# SAM9X60 device description
Architecture: ARM926EJS; Family: SAM9; Series: SAM9X
Registers are 32-bit, read-write, no defined reset value unless marked. A register's access mark holds for its fields unless they carry their own. Offsets are from the block's base; [hi:lo] are bit positions; {n}, {i} and the like mark numbered series; 'fields as' and 'values as' point back to an identical list.

## OTPC — OTP Memory Controller
Instances: OTPC 0xEFF00000
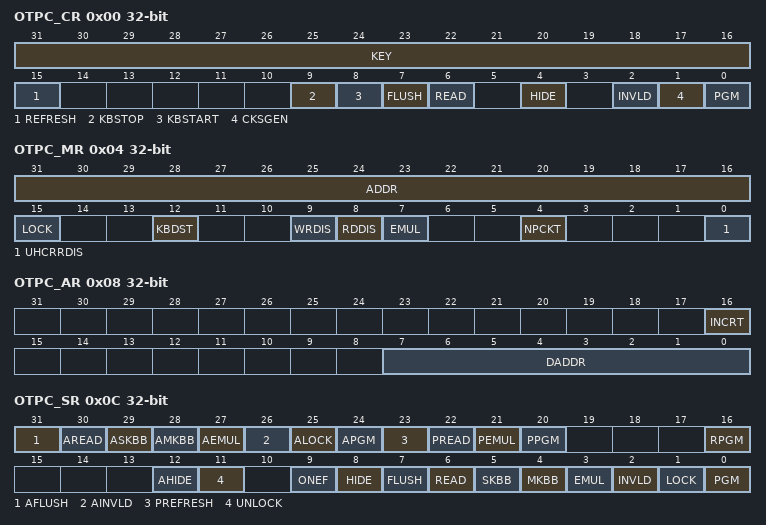
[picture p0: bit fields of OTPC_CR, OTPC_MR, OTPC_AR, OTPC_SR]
0x00 OTPC_CR wo — Control Register
  [31:16] KEY — Programming Key
  [15] REFRESH — Refresh the Area
  [9] KBSTOP — Key Bus Transfer Stop
  [8] KBSTART — Key Bus Transfer Start
  [7] FLUSH — Flush Temporary Registers
  [6] READ — Read Area
  [4] HIDE — Hide Packet
  [2] INVLD — Invalidate Packet
  [1] CKSGEN — Generate Checksum
  [0] PGM — Program Packet
0x04 OTPC_MR — Mode Register
  [31:16] ADDR — Address
  [15] LOCK
  [12] KBDST — Key Bus Destination
    0=TDES (The TDES is the destination of the key transfer.); 1=AES (The AES is the destination of the key transfer.)
  [9] WRDIS — Write Disable
  [8] RDDIS — Read Disable
  [7] EMUL — Emulation Enable
  [4] NPCKT — New Packet
  [0] UHCRRDIS — User Hardware Configuration Register Read Disable
0x08 OTPC_AR — Address Register
  [16] INCRT — Increment Type
    0=AFTER_READ (Increment DADDR after a read of OTPC_DR.); 1=AFTER_WRITE (Increment DADDR after a write of OTPC_DR.)
  [7:0] DADDR — Data Address
0x0C OTPC_SR ro — Status Register
  [31] AFLUSH — Engineering Flush On-Going
  [30] AREAD — Engineering Read On-Going
  [29] ASKBB — Engineering Slave Key Bus Busy
  [28] AMKBB — Engineering Master Key Bus Busy
  [27] AEMUL — Engineering Emulation Enabled
  [26] AINVLD — Engineering Invalidation On-Going
  [25] ALOCK — Engineering Lock On-Going
  [24] APGM — Engineering Programming On-Going
  [23] PREFRESH — Patch Refresh On-Going
  [22] PREAD — Patch Read On-Going
  [21] PEMUL — Patch Emulation Enabled
  [20] PPGM — Patch Programming On-Going
  [16] RPGM — ROM Programming On-Going
  [12] AHIDE — Hiding On-Going
  [11] UNLOCK — OTP Registers Unlocked
  [9] ONEF — One Found
  [8] HIDE — Hiding On-Going
  [7] FLUSH — Flush On-Going
  [6] READ — Read On-Going
  [5] SKBB — Slave Key Bus Busy
  [4] MKBB — Master Key Bus Busy
  [3] EMUL — Emulation Enabled
  [2] INVLD — Invalidation On-Going
  [1] LOCK — Lock On-Going
  [0] PGM — Programming On-Going
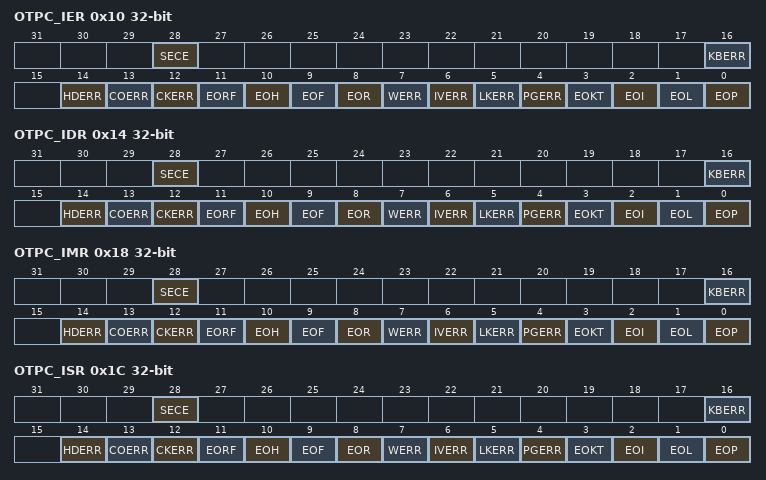
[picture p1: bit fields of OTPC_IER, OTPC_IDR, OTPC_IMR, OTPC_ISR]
0x10 OTPC_IER wo — Interrupt Enable Register
  [28] SECE — Security and/or Safety Event Interrupt Enable
  [16] KBERR — Key Bus Error Interrupt Enable
  [14] HDERR — Hide Error Interrupt Enable
  [13] COERR — Corruption Error Interrupt Enable
  [12] CKERR — Checksum Check Error Interrupt Enable
  [11] EORF — End Of Refresh Interrupt Enable
  [10] EOH — End Of Hide Interrupt Enable
  [9] EOF — End Of Flush Interrupt Enable
  [8] EOR — End Of Read Interrupt Enable
  [7] WERR — Write Error Interrupt Enable
  [6] IVERR — Invalidation Error Interrupt Enable
  [5] LKERR — Locking Error Interrupt Enable
  [4] PGERR — Programming Error Interrupt Enable
  [3] EOKT — End Of Key Transfer Interrupt Enable
  [2] EOI — End Of Invalidation Interrupt Enable
  [1] EOL — End Of Locking Interrupt Enable
  [0] EOP — End Of Programming Interrupt Enable
0x14 OTPC_IDR wo — Interrupt Disable Register
  [28] SECE — Security and/or Safety Event Interrupt Disable
  [16] KBERR — Key Bus Error Interrupt Disable
  [14] HDERR — Hide Error Interrupt Disable
  [13] COERR — Corruption Error Interrupt Disable
  [12] CKERR — Checksum Check Error Interrupt Disable
  [11] EORF — End Of Refresh Interrupt Disable
  [10] EOH — End Of Hide Interrupt Disable
  [9] EOF — End Of Flush Interrupt Disable
  [8] EOR — End Of Read Interrupt Disable
  [7] WERR — Write Error Interrupt Disable
  [6] IVERR — Invalidation Error Interrupt Disable
  [5] LKERR — Locking Error Interrupt Disable
  [4] PGERR — Programming Error Interrupt Disable
  [3] EOKT — End Of Key Transfer Interrupt Disable
  [2] EOI — End Of Invalidation Interrupt Disable
  [1] EOL — End Of Locking Interrupt Disable
  [0] EOP — End Of Programming Interrupt Disable
0x18 OTPC_IMR ro — Interrupt Mask Register
  [28] SECE — Security and/or Safety Event Interrupt Mask
  [16] KBERR — Key Bus Error Interrupt Mask
  [14] HDERR — Hide Error Interrupt Mask
  [13] COERR — Corruption Error Interrupt Mask
  [12] CKERR — Checksum Check Error Interrupt Mask
  [11] EORF — End Of Refresh Interrupt Mask
  [10] EOH — End Of Hide Interrupt Mask
  [9] EOF — End Of Flush Interrupt Mask
  [8] EOR — End Of Read Interrupt Mask
  [7] WERR — Write Error Interrupt Mask
  [6] IVERR — Invalidation Error Interrupt Mask
  [5] LKERR — Locking Error Interrupt Mask
  [4] PGERR — Programming Error Interrupt Mask
  [3] EOKT — End Of Key Transfer Interrupt Mask
  [2] EOI — End Of Invalidation Interrupt Mask
  [1] EOL — End Of Locking Interrupt Mask
  [0] EOP — End Of Programming Interrupt Mask
0x1C OTPC_ISR ro — Interrupt Status Register
  [28] SECE — Security and/or Safety Event (cleared on read)
  [16] KBERR — Key Bus Error (cleared on read)
  [14] HDERR — Hide Error (cleared on read)
  [13] COERR — Corruption Error (cleared on read)
  [12] CKERR — Checksum Check Error (cleared on read)
  [11] EORF — End Of Refresh (cleared on read)
  [10] EOH — End Of Hide (cleared on read)
  [9] EOF — End Of Flush (cleared on read)
  [8] EOR — End Of Read (cleared on read)
  [7] WERR — Write Error (cleared on read)
  [6] IVERR — Invalidation Error (cleared on read)
  [5] LKERR — Locking Error (cleared on read)
  [4] PGERR — Programming Error (cleared on read)
  [3] EOKT — End Of Key Transfer (cleared on read)
  [2] EOI — End Of Invalidation (cleared on read)
  [1] EOL — End Of Locking (cleared on read)
  [0] EOP — End Of Programming (cleared on read)
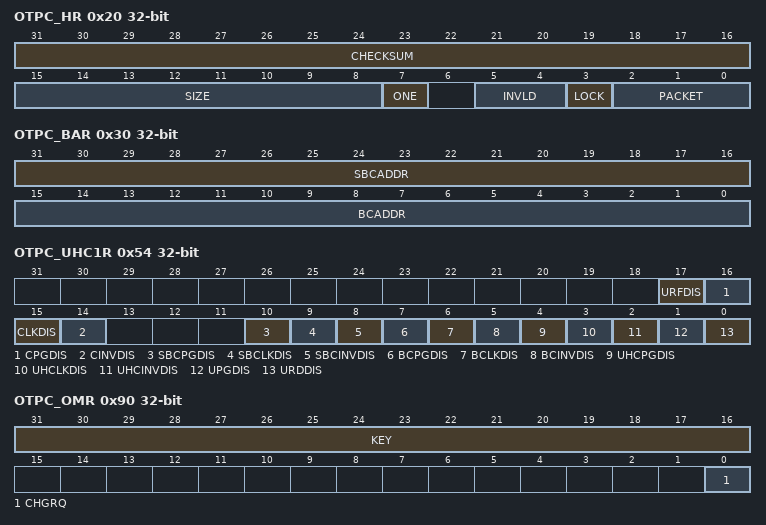
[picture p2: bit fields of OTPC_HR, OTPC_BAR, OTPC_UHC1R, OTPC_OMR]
0x20 OTPC_HR — Header Register
  [31:16] CHECKSUM — Packet Checksum
  [15:8] SIZE — Packet Size
  [7] ONE
  [5:4] INVLD — Invalid Status
  [3] LOCK — Lock Status
  [2:0] PACKET — Packet Type
    1=REGULAR (Regular packet accessible through the User Interface); 2=KEY (Key packet accessible only through the Key Buses); 3=BOOT_CONFIGURATION (Boot Configuration packet); 4=SECURE_BOOT_CONFIGURATION (Secure Boot Configuration packet); 5=HARDWARE_CONFIGURATION (Hardware Configuration packet); 6=CUSTOM (Custom packet)
0x24 OTPC_DR — Data Register
  [31:0] DATA — Packet Data
0x30 OTPC_BAR ro — Boot Addresses Register
  [31:16] SBCADDR — Secure Boot Configuration Address
  [15:0] BCADDR — Boot Configuration Address
0x34 OTPC_CAR ro — Custom Address Register
  [15:0] CADDR — Custom Address
0x50 OTPC_UHC0R ro — User Hardware Configuration 0 Register
  [7:0] JTAGDIS — JTAG Disable
0x54 OTPC_UHC1R ro — User Hardware Configuration 1 Register
  [17] URFDIS — User Refresh Disable
  [16] CPGDIS — Custom Packet Program Disable
  [15] CLKDIS — Custom Packet Lock Disable
  [14] CINVDIS — Custom Packet Invalidation Disable
  [10] SBCPGDIS — Secure Boot Configuration Packet Program Disable
  [9] SBCLKDIS — Secure Boot Configuration Packet Lock Disable
  [8] SBCINVDIS — Secure Boot Configuration Packet Invalidation Disable
  [7] BCPGDIS — Boot Configuration Packet Program Disable
  [6] BCLKDIS — Boot Configuration Packet Lock Disable
  [5] BCINVDIS — Boot Configuration Packet Invalidation Disable
  [4] UHCPGDIS — User Hardware Configuration Packet Program Disable
  [3] UHCLKDIS — User Hardware Configuration Packet Lock Disable
  [2] UHCINVDIS — User Hardware Configuration Packet Invalidation Disable
  [1] UPGDIS — User programming Disable
  [0] URDDIS — User Read Disable
{0x60+4i} OTPC_UID{i}R ro (i=0..3) — Product UID Register {i}
  [31:0] UID — Unique Product ID
0x70 OTPC_HCSR — Hardware Configuration Selection Register
  [3:0] HCSEL — Hardware Configuration Selection
0x74 OTPC_HCDR ro — Hardware Configuration Data Register
  [31:0] HCFG — Hardware Configuration Value
0x80 OTPC_HS0R ro — Hardware Security Register 0
  [31:0] SCFG — Security Configuration Value
0x84 OTPC_HS1R ro — Hardware Security Register 1
  [31:0] SCFG — Security Configuration Value
0x90 OTPC_OMR — OTP Mode Register
  [31:16] KEY
  [0] CHGRQ — Change Request
{0xA0+4i} OTPC_ODC{i}R (i=0..3) — OTP DAP Configuration Register {i}
  [31:0] DAPCFG — DAP Configuration
{0xB0+4i} OTPC_OPC{i}R (i=0..3) — OTP PMC Configuration Register {i}
  [31:0] PMCCFG — PMC Configuration
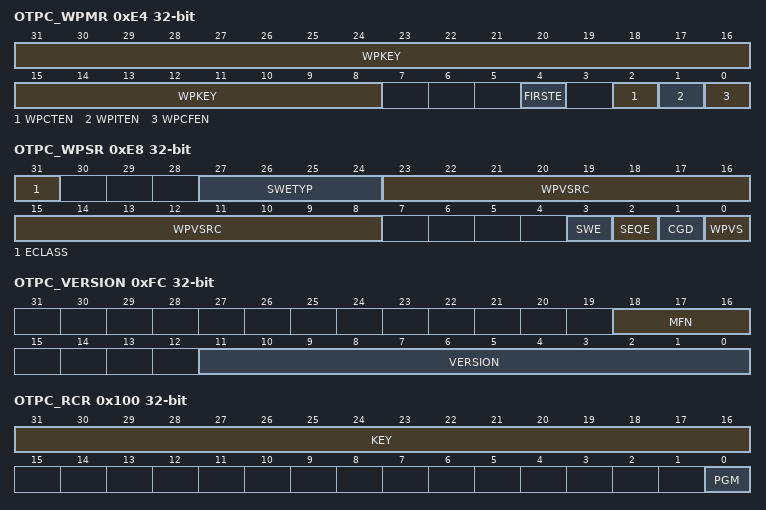
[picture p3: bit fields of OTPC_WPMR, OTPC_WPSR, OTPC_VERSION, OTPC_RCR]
0xE4 OTPC_WPMR — Write Protection Mode Register
  [31:8] WPKEY — Write Protection Key
    0x4F5450=PASSWD (Writing any other value in this field aborts the write operation. Always reads as 0.)
  [4] FIRSTE — First Error Report Enable
  [2] WPCTEN — Write Protection Control Enable
  [1] WPITEN — Write Protection Interrupt Enable
  [0] WPCFEN — Write Protection Configuration Enable
0xE8 OTPC_WPSR ro — Write Protection Status Register
  [31] ECLASS — Software Error Class
    0=WARNING (An abnormal access that does not have any impact.); 1=ERROR (An abnormal access that may have an impact.)
  [27:24] SWETYP — Software Error Type
    0=READ_WO (A write-only register has been read (warning).); 1=WRITE_RO (A write access has been performed on a read-only register (warning).); 2=CONF_CHG (A change has been made into the configuration (error).); 3=KEY_ERROR (A write has been computed in OTPC_CR, OTPC_ACR, OTPC_RCR, OTPC_PCR, OTPC_OMR or OTPC_WPMR register with a wrong value in the related KEY field (error).)
  [23:8] WPVSRC — Write Protection Violation Source
  [3] SWE — Software Control Error (cleared on read)
  [2] SEQE — Internal Sequencer Error (cleared on read)
  [1] CGD — Clock Glitch Detected (cleared on read)
  [0] WPVS — Write Protection Violation Status (cleared on read)
0xFC OTPC_VERSION ro — Version Register
  [18:16] MFN — Metal Fix Number
  [11:0] VERSION — Hardware Module Version
0x100 OTPC_RCR wo — ROM Control Register
  [31:16] KEY — Programming Key
  [0] PGM — Program
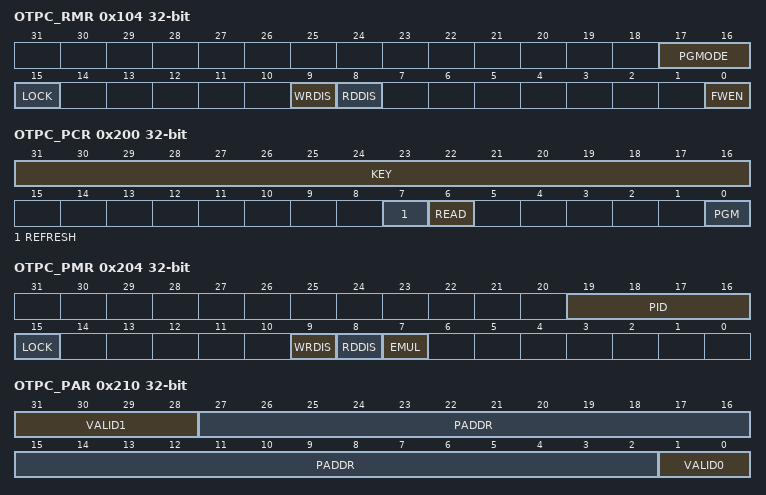
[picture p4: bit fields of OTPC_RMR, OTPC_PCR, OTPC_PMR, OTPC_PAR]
0x104 OTPC_RMR — ROM Mode Register
  [17:16] PGMODE — Programming Mode
    0=ROM_NO_PGM (ROM Code programming is disabled); 1=ROM_SBUS_PGM (ROM Code programming through System Bus Slave Interface); 2=ROM_UI_ADDR_CONST_PGM (ROM Code programming through User Interface); 3=ROM_UI_ADDR_INCR_PGM (ROM Code programming through User Interface with OTPC_RAR incremented after each programming.)
  [15] LOCK
  [9] WRDIS — Write Disable
  [8] RDDIS — Read Disable
  [0] FWEN — Firewall Enable
0x110 OTPC_RAR — ROM Address Register
  [31:2] RADDR — ROM Address
0x114 OTPC_RDR — ROM Data Register
  [31:0] RDATA — ROM Data
0x200 OTPC_PCR wo — Patch Control Register
  [31:16] KEY — Programming Key
  [7] REFRESH — Refresh Patches
  [6] READ — Read Patch
  [0] PGM — Program
0x204 OTPC_PMR — Patch Mode Register
  [19:16] PID — Patch ID
  [15] LOCK
  [9] WRDIS — Write Disable
  [8] RDDIS — Read Disable
  [7] EMUL — Emulation Mode
0x208 OTPC_PSR — Patch Software Register
  [31:0] SOFT — Software Value
0x210 OTPC_PAR — Patch Address Register
  [31:28] VALID1 — Patch Validity
  [27:2] PADDR — Patch Address
  [1:0] VALID0 — Patch Validity
0x214 OTPC_PDR — Patch Data Register
  [31:0] PDATA — Patch Data
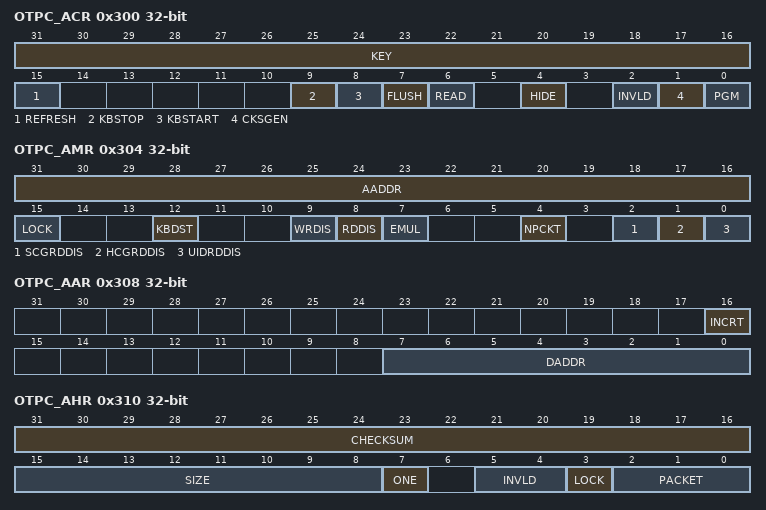
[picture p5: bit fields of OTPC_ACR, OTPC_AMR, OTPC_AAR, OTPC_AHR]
0x300 OTPC_ACR wo — A Control Register
  fields as OTPC_CR
0x304 OTPC_AMR — A Mode Register
  [31:16] AADDR — Address
  [15] LOCK
  [12] KBDST — Key Bus Destination
    values as OTPC_MR.KBDST
  [9] WRDIS — Write Disable
  [8] RDDIS — Read Disable
  [7] EMUL — Emulation Mode
  [4] NPCKT — New Packet
  [2] SCGRDDIS — Security Configuration Register Read Disable
  [1] HCGRDDIS — Hardware Configuration Register Read Disable
  [0] UIDRDDIS — UID Register Read Disable
0x308 OTPC_AAR — A Address Register
  [16] INCRT — Increment Type
    0=AFTER_READ (Increment DADDR after a read of OTPC_ADR.); 1=AFTER_WRITE (Increment DADDR after a write of OTPC_ADR.)
  [7:0] DADDR — Data Address
0x310 OTPC_AHR — A Header Register
  [31:16] CHECKSUM — Packet Checksum
  [15:8] SIZE — Packet Size
  [7] ONE
  [5:4] INVLD — Invalid Status
  [3] LOCK — Lock Status
  [2:0] PACKET — Packet Type
    1=REGULAR (Regular packet accessible through the User Interface.); 2=KEY (Key packet accessible only through the Key buses.); 4=PRODUCT_UID (Product UID packet.); 5=HARDWARE_CONFIGURATION (Hardware Configuration packet.); 6=SECURITY_CONFIGURATION (Security Configuration packet.)
0x314 OTPC_ADR — A Data Register
  [31:0] ADATA — Engineering Packet Data
